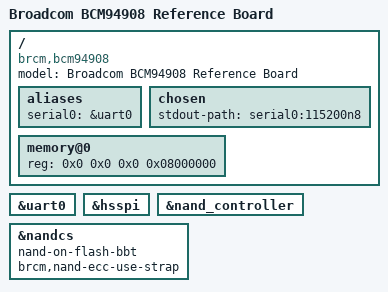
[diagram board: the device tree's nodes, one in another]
// SPDX-License-Identifier: (GPL-2.0+ OR MIT)
/*
 * Copyright 2022 Broadcom Ltd.
 */

/dts-v1/;

#include "bcm4908.dtsi"

/ {
	model = "Broadcom BCM94908 Reference Board";
	compatible = "brcm,bcm94908", "brcm,bcm4908", "brcm,bcmbca";

	aliases {
		serial0 = &uart0;
	};

	chosen {
		stdout-path = "serial0:115200n8";
	};

	memory@0 {
		device_type = "memory";
		reg = <0x0 0x0 0x0 0x08000000>;
	};
};

&uart0 {
	status = "okay";
};

&hsspi {
	status = "okay";
};

&nand_controller {
	status = "okay";
};

&nandcs {
	nand-on-flash-bbt;
	brcm,nand-ecc-use-strap;
};
